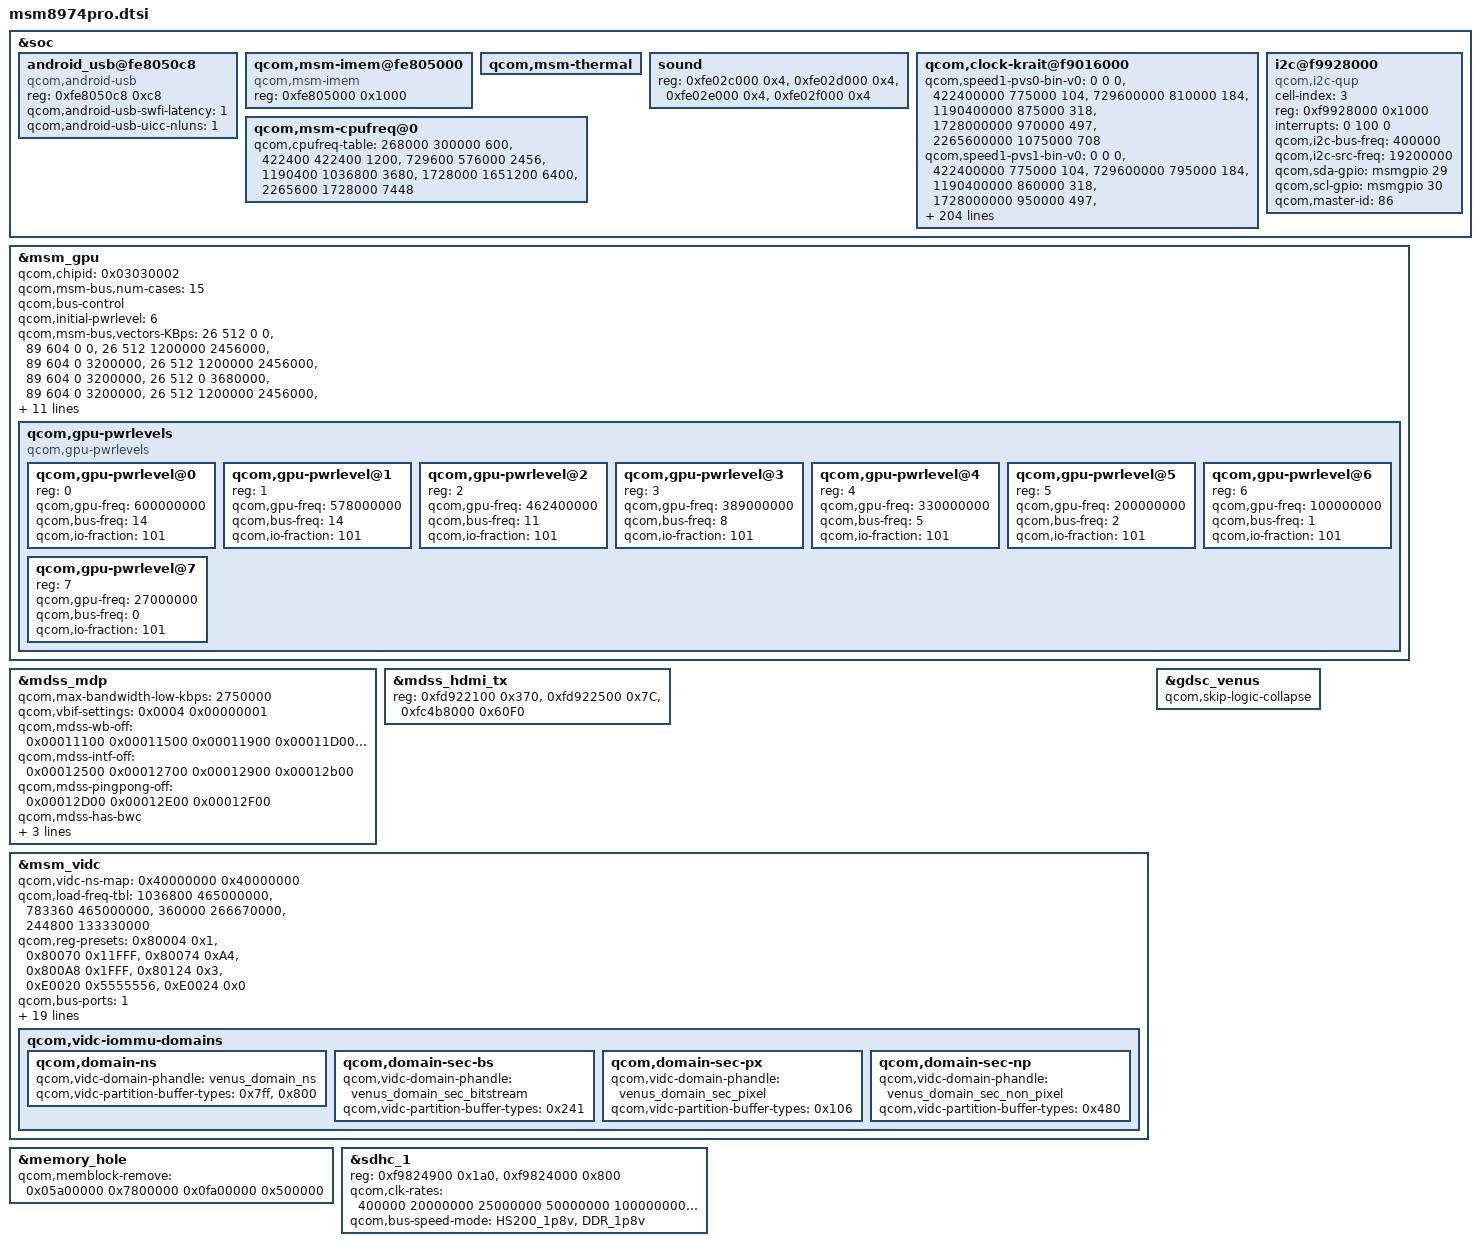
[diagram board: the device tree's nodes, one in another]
/* Copyright (c) 2013-2014, The Linux Foundation. All rights reserved.
 *
 * This program is free software; you can redistribute it and/or modify
 * it under the terms of the GNU General Public License version 2 and
 * only version 2 as published by the Free Software Foundation.
 *
 * This program is distributed in the hope that it will be useful,
 * but WITHOUT ANY WARRANTY; without even the implied warranty of
 * MERCHANTABILITY or FITNESS FOR A PARTICULAR PURPOSE.  See the
 * GNU General Public License for more details.
 */

/*
 * As a general rule, only version-specific property overrides should be placed
 * inside this file. However, device definitions should be placed inside the
 * msm8974.dtsi file.
 */

/include/ "msm8974.dtsi"
/include/ "msm8974-v2-iommu.dtsi"
/include/ "msm8974-v2-iommu-domains.dtsi"
/include/ "msm8974pro-pm.dtsi"
/include/ "msm8974pro-ion.dtsi"

&soc {
	android_usb@fe8050c8 {
		compatible = "qcom,android-usb";
		reg = <0xfe8050c8 0xc8>;
		qcom,android-usb-swfi-latency = <1>;
		qcom,android-usb-uicc-nluns = /bits/ 8 <1>;
	};

	qcom,msm-imem@fe805000 {
		compatible = "qcom,msm-imem";
		reg = <0xfe805000 0x1000>; /* Address and size of IMEM */
	};

	qcom,msm-thermal {
		/delete-property/ qcom,pmic-sw-mode-temp;
		/delete-property/ qcom,pmic-sw-mode-temp-hysteresis;
		/delete-property/ qcom,pmic-sw-mode-regs;
	};

	sound {
		reg = <0xfe02c000 0x4>,
		      <0xfe02d000 0x4>,
		      <0xfe02e000 0x4>,
		      <0xfe02f000 0x4>;
		reg-names = "lpaif_pri_mode_muxsel",
			    "lpaif_sec_mode_muxsel",
			    "lpaif_tert_mode_muxsel",
			    "lpaif_quat_mode_muxsel";
	};

	qcom,clock-krait@f9016000 {
		qcom,speed1-pvs0-bin-v0 =
			<          0       0    0 >,
			<  422400000  775000  104 >,
			<  729600000  810000  184 >,
			< 1190400000  875000  318 >,
			< 1728000000  970000  497 >,
			< 2265600000 1075000  708 >;

		qcom,speed1-pvs1-bin-v0 =
			<          0       0    0 >,
			<  422400000  775000  104 >,
			<  729600000  795000  184 >,
			< 1190400000  860000  318 >,
			< 1728000000  950000  497 >,
			< 2265600000 1050000  708 >;

		qcom,speed1-pvs2-bin-v0 =
			<          0       0    0 >,
			<  422400000  750000  104 >,
			<  729600000  780000  184 >,
			< 1190400000  840000  318 >,
			< 1728000000  930000  497 >,
			< 2265600000 1025000  708 >;

		qcom,speed1-pvs3-bin-v0 =
			<          0       0    0 >,
			<  422400000  750000  104 >,
			<  729600000  765000  184 >,
			< 1190400000  825000  318 >,
			< 1728000000  910000  497 >,
			< 2265600000 1000000  708 >;

		qcom,speed1-pvs4-bin-v0 =
			<          0       0    0 >,
			<  422400000  750000  104 >,
			<  729600000  755000  184 >,
			< 1190400000  815000  318 >,
			< 1728000000  895000  497 >,
			< 2265600000  975000  708 >;

		qcom,speed1-pvs5-bin-v0 =
			<          0       0    0 >,
			<  422400000  725000  104 >,
			<  729600000  745000  184 >,
			< 1190400000  805000  318 >,
			< 1728000000  875000  497 >,
			< 2265600000  950000  708 >;

		qcom,speed1-pvs6-bin-v0 =
			<          0       0    0 >,
			<  422400000  725000  104 >,
			<  729600000  735000  184 >,
			< 1190400000  795000  318 >,
			< 1728000000  860000  497 >,
			< 2265600000  925000  708 >;

		qcom,speed3-pvs0-bin-v0 =
			<          0       0    0 >,
			<  422400000  800000  106 >,
			<  729600000  820000  186 >,
			< 1190400000  880000  319 >,
			< 1728000000  960000  493 >,
			< 2265600000 1065000  700 >;

		qcom,speed3-pvs1-bin-v0 =
			<          0       0    0 >,
			<  422400000  800000  106 >,
			<  729600000  800000  186 >,
			< 1190400000  855000  319 >,
			< 1728000000  935000  493 >,
			< 2265600000 1040000  700 >;

		qcom,speed3-pvs2-bin-v0 =
			<          0       0    0 >,
			<  422400000  775000  106 >,
			<  729600000  775000  186 >,
			< 1190400000  830000  319 >,
			< 1728000000  910000  493 >,
			< 2265600000 1015000  700 >;

		qcom,speed3-pvs3-bin-v0 =
			<          0       0    0 >,
			<  422400000  775000  106 >,
			<  729600000  775000  186 >,
			< 1190400000  805000  319 >,
			< 1728000000  885000  493 >,
			< 2265600000  990000  700 >;

		qcom,speed3-pvs4-bin-v0 =
			<          0       0    0 >,
			<  422400000  775000  106 >,
			<  729600000  775000  186 >,
			< 1190400000  780000  319 >,
			< 1728000000  860000  493 >,
			< 2265600000  965000  700 >;

		qcom,speed3-pvs5-bin-v0 =
			<          0       0    0 >,
			<  422400000  750000  106 >,
			<  729600000  750000  186 >,
			< 1190400000  760000  319 >,
			< 1728000000  835000  493 >,
			< 2265600000  940000  700 >;

		qcom,speed3-pvs6-bin-v0 =
			<          0       0    0 >,
			<  422400000  750000  106 >,
			<  729600000  750000  186 >,
			< 1190400000  750000  319 >,
			< 1728000000  815000  493 >,
			< 2265600000  940000  700 >;

		qcom,speed1-pvs0-bin-v1 =
			<          0       0    0 >,
			<  268000000  800000   76 >,
			<  422400000  820000  108 >,
			<  729600000  860000  193 >,
			< 1190400000  920000  330 >,
			< 1728000000 1015000  515 >,
			< 2265600000 1120000  738 >;

		qcom,speed1-pvs1-bin-v1 =
			<          0       0    0 >,
			<  268000000  800000   76 >,
			<  422400000  810000  108 >,
			<  729600000  850000  193 >,
			< 1190400000  910000  330 >,
			< 1728000000 1005000  515 >,
			< 2265600000 1110000  738 >;

		qcom,speed1-pvs2-bin-v1 =
			<          0       0    0 >,
			<  268000000  800000   76 >,
			<  422400000  800000  108 >,
			<  729600000  840000  193 >,
			< 1190400000  900000  330 >,
			< 1728000000  995000  515 >,
			< 2265600000 1100000  738 >;

		qcom,speed1-pvs3-bin-v1 =
			<          0       0    0 >,
			<  268000000  800000   76 >,
			<  422400000  800000  108 >,
			<  729600000  830000  193 >,
			< 1190400000  890000  330 >,
			< 1728000000  985000  515 >,
			< 2265600000 1090000  738 >;

		qcom,speed1-pvs4-bin-v1 =
			<          0       0    0 >,
			<  268000000  800000   76 >,
			<  422400000  800000  108 >,
			<  729600000  820000  193 >,
			< 1190400000  880000  330 >,
			< 1728000000  975000  515 >,
			< 2265600000 1080000  738 >;

		qcom,speed1-pvs5-bin-v1 =
			<          0       0    0 >,
			<  268000000  800000   76 >,
			<  422400000  800000  108 >,
			<  729600000  810000  193 >,
			< 1190400000  870000  330 >,
			< 1728000000  965000  515 >,
			< 2265600000 1070000  738 >;

		qcom,speed1-pvs6-bin-v1 =
			<          0       0    0 >,
			<  268000000  775000   76 >,
			<  422400000  775000  108 >,
			<  729600000  805000  193 >,
			< 1190400000  865000  330 >,
			< 1728000000  955000  515 >,
			< 2265600000 1060000  738 >;

		qcom,speed1-pvs7-bin-v1 =
			<          0       0    0 >,
			<  268000000  775000   76 >,
			<  422400000  775000  108 >,
			<  729600000  800000  193 >,
			< 1190400000  860000  330 >,
			< 1728000000  945000  515 >,
			< 2265600000 1050000  738 >;

		qcom,speed1-pvs8-bin-v1 =
			<          0       0    0 >,
			<  268000000  775000   76 >,
			<  422400000  775000  108 >,
			<  729600000  790000  193 >,
			< 1190400000  850000  330 >,
			< 1728000000  935000  515 >,
			< 2265600000 1040000  738 >;

		qcom,speed1-pvs9-bin-v1 =
			<          0       0    0 >,
			<  268000000  775000   76 >,
			<  422400000  775000  108 >,
			<  729600000  785000  193 >,
			< 1190400000  845000  330 >,
			< 1728000000  925000  515 >,
			< 2265600000 1030000  738 >;

		qcom,speed1-pvs10-bin-v1 =
			<          0       0    0 >,
			<  268000000  775000   76 >,
			<  422400000  775000  108 >,
			<  729600000  780000  193 >,
			< 1190400000  840000  330 >,
			< 1728000000  915000  515 >,
			< 2265600000 1020000  738 >;

		qcom,speed1-pvs11-bin-v1 =
			<          0       0    0 >,
			<  268000000  775000   76 >,
			<  422400000  775000  108 >,
			<  729600000  775000  193 >,
			< 1190400000  835000  330 >,
			< 1728000000  905000  515 >,
			< 2265600000 1010000  738 >;

		qcom,speed1-pvs12-bin-v1 =
			<          0       0    0 >,
			<  268000000  775000   76 >,
			<  422400000  775000  108 >,
			<  729600000  775000  193 >,
			< 1190400000  830000  330 >,
			< 1728000000  900000  515 >,
			< 2265600000 1000000  738 >;

		qcom,speed1-pvs13-bin-v1 =
			<          0       0    0 >,
			<  268000000  775000   76 >,
			<  422400000  775000  108 >,
			<  729600000  775000  193 >,
			< 1190400000  825000  330 >,
			< 1728000000  895000  515 >,
			< 2265600000  990000  738 >;

		qcom,speed1-pvs14-bin-v1 =
			<          0       0    0 >,
			<  268000000  750000   76 >,
			<  422400000  750000  108 >,
			<  729600000  760000  193 >,
			< 1190400000  820000  330 >,
			< 1728000000  890000  515 >,
			< 2265600000  980000  738 >;

		qcom,speed1-pvs15-bin-v1 =
			<          0       0    0 >,
			<  268000000  750000   76 >,
			<  422400000  750000  108 >,
			<  729600000  755000  193 >,
			< 1190400000  815000  330 >,
			< 1728000000  885000  515 >,
			< 2265600000  970000  738 >;

		qcom,speed3-pvs0-bin-v1 =
			<          0       0    0 >,
			<  422400000  800000  106 >,
			<  729600000  840000  189 >,
			< 1190400000  900000  324 >,
			< 1728000000  980000  501 >,
			< 2265600000 1085000  716 >;

		qcom,speed3-pvs1-bin-v1 =
			<          0       0    0 >,
			<  422400000  800000  106 >,
			<  729600000  830000  189 >,
			< 1190400000  890000  324 >,
			< 1728000000  970000  501 >,
			< 2265600000 1075000  716 >;

		qcom,speed3-pvs2-bin-v1 =
			<          0       0    0 >,
			<  422400000  800000  106 >,
			<  729600000  820000  189 >,
			< 1190400000  880000  324 >,
			< 1728000000  960000  501 >,
			< 2265600000 1065000  716 >;

		qcom,speed3-pvs3-bin-v1 =
			<          0       0    0 >,
			<  422400000  800000  106 >,
			<  729600000  810000  189 >,
			< 1190400000  870000  324 >,
			< 1728000000  950000  501 >,
			< 2265600000 1055000  716 >;

		qcom,speed3-pvs4-bin-v1 =
			<          0       0    0 >,
			<  422400000  800000  106 >,
			<  729600000  800000  189 >,
			< 1190400000  860000  324 >,
			< 1728000000  940000  501 >,
			< 2265600000 1045000  716 >;

		qcom,speed3-pvs5-bin-v1 =
			<          0       0    0 >,
			<  422400000  800000  106 >,
			<  729600000  800000  189 >,
			< 1190400000  850000  324 >,
			< 1728000000  930000  501 >,
			< 2265600000 1035000  716 >;

		qcom,speed3-pvs6-bin-v1 =
			<          0       0    0 >,
			<  422400000  775000  106 >,
			<  729600000  780000  189 >,
			< 1190400000  840000  324 >,
			< 1728000000  920000  501 >,
			< 2265600000 1025000  716 >;

		qcom,speed3-pvs7-bin-v1 =
			<          0       0    0 >,
			<  422400000  775000  106 >,
			<  729600000  780000  189 >,
			< 1190400000  835000  324 >,
			< 1728000000  910000  501 >,
			< 2265600000 1015000  716 >;

		qcom,speed3-pvs8-bin-v1 =
			<          0       0    0 >,
			<  422400000  775000  106 >,
			<  729600000  775000  189 >,
			< 1190400000  825000  324 >,
			< 1728000000  900000  501 >,
			< 2265600000 1005000  716 >;

		qcom,speed3-pvs9-bin-v1 =
			<          0       0    0 >,
			<  422400000  775000  106 >,
			<  729600000  775000  189 >,
			< 1190400000  820000  324 >,
			< 1728000000  890000  501 >,
			< 2265600000  995000  716 >;

		qcom,speed3-pvs10-bin-v1 =
			<          0       0    0 >,
			<  422400000  775000  106 >,
			<  729600000  775000  189 >,
			< 1190400000  815000  324 >,
			< 1728000000  885000  501 >,
			< 2265600000  985000  716 >;

		qcom,speed3-pvs11-bin-v1 =
			<          0       0    0 >,
			<  422400000  775000  106 >,
			<  729600000  775000  189 >,
			< 1190400000  810000  324 >,
			< 1728000000  880000  501 >,
			< 2265600000  975000  716 >;

		qcom,speed3-pvs12-bin-v1 =
			<          0       0    0 >,
			<  422400000  775000  106 >,
			<  729600000  775000  189 >,
			< 1190400000  805000  324 >,
			< 1728000000  875000  501 >,
			< 2265600000  965000  716 >;

		qcom,speed3-pvs13-bin-v1 =
			<          0       0    0 >,
			<  422400000  775000  106 >,
			<  729600000  775000  189 >,
			< 1190400000  800000  324 >,
			< 1728000000  870000  501 >,
			< 2265600000  955000  716 >;

		qcom,speed3-pvs14-bin-v1 =
			<          0       0    0 >,
			<  422400000  750000  106 >,
			<  729600000  750000  189 >,
			< 1190400000  795000  324 >,
			< 1728000000  865000  501 >,
			< 2265600000  945000  716 >;

		qcom,speed3-pvs15-bin-v1 =
			<          0       0    0 >,
			<  422400000  750000  106 >,
			<  729600000  750000  189 >,
			< 1190400000  790000  324 >,
			< 1728000000  860000  501 >,
			< 2265600000  935000  716 >;
	};

	qcom,msm-cpufreq@0 {
		qcom,cpufreq-table =
			<  268000  300000  600 /*  75 MHz */ >,
			<  422400  422400 1200 /* 150 MHz */ >,
			<  729600  576000 2456 /* 307 MHz */ >,
			< 1190400 1036800 3680 /* 460 MHz */ >,
			< 1728000 1651200 6400 /* 800 MHz */ >,
			< 2265600 1728000 7448 /* 931 MHz */ >;

	};

	i2c@f9928000 { /* BLSP-1 QUP-6 */
		cell-index = <3>;
		compatible = "qcom,i2c-qup";
		reg = <0xf9928000 0x1000>;
		#address-cells = <1>;
		#size-cells = <0>;
		reg-names = "qup_phys_addr";
		interrupts = <0 100 0>;
		interrupt-names = "qup_err_intr";
		qcom,i2c-bus-freq = <400000>;
		qcom,i2c-src-freq = <19200000>;
		qcom,sda-gpio = <&msmgpio 29 0>;
		qcom,scl-gpio = <&msmgpio 30 0>;
		qcom,master-id = <86>;
	};
};

/* GPU overrides */
&msm_gpu {
	/* Updated chip ID */
	qcom,chipid = <0x03030002>;
	qcom,msm-bus,num-cases = <15>;
	qcom,bus-control;
	qcom,initial-pwrlevel = <6>;

	/* Updated bus bandwidth requirements */
	qcom,msm-bus,vectors-KBps =
		/* Off */
		<26 512 0 0>, <89 604 0 0>,
		/* Sub-SVS / SVS */
		<26 512 1200000 2456000>, <89 604 0 3200000>,
		/* SVS */
		<26 512 1200000 2456000>, <89 604 0 3200000>,
		/* low Nominal / SVS */
		<26 512 0 3680000>, <89 604 0 3200000>,
		/* SVS / low Nominal */
		<26 512 1200000 2456000>, <89 604 0 5280000>,
		/* low Nominal / low Nominal */
		<26 512 0 3680000>, <89 604 0 5280000>,
		/* Nominal / low Nominal */
		<26 512 0 4912000>, <89 604 0 5280000>,
		/* low Nominal / Nominal */
		<26 512 0 3680000>, <89 604 0 6224000>,
		/* Nominal / Nominal */
		<26 512 0 4912000>, <89 604 0 6224000>,
		/* low Turbo / Nominal */
		<26 512 0 6400000>, <89 604 0 6224000>,
		/* Nominal / low Turbo */
		<26 512 0 4912000>, <89 604 0 7398000>,
		/* low Turbo / low Turbo */
		<26 512 0 6400000>, <89 604 0 7398000>,
		/* Turbo / low Turbo */
		<26 512 0 7464000>, <89 604 0 7398000>,
		/* Nominal / Turbo */
		<26 512 0 4912000>, <89 604 0 9248000>,
		/* Turbo / Turbo */
		<26 512 0 7464000>, <89 604 0 9248000>;

       qcom,gpu-pwrlevels {
               #address-cells = <1>;
               #size-cells = <0>;

               compatible = "qcom,gpu-pwrlevels";

		qcom,gpu-pwrlevel@0 {
                       reg = <0>;
                       qcom,gpu-freq = <600000000>;
                       qcom,bus-freq = <14>;
                       qcom,io-fraction = <101>;
               };

               qcom,gpu-pwrlevel@1 {
                       reg = <1>;
                       qcom,gpu-freq = <578000000>;
                       qcom,bus-freq = <14>;
                       qcom,io-fraction = <101>;
               };

               qcom,gpu-pwrlevel@2 {
                       reg = <2>;
                       qcom,gpu-freq = <462400000>;
                       qcom,bus-freq = <11>;
                       qcom,io-fraction = <101>;
               };

               qcom,gpu-pwrlevel@3 {
                       reg = <3>;
                       qcom,gpu-freq = <389000000>;
                       qcom,bus-freq = <8>;
                       qcom,io-fraction = <101>;
               };

               qcom,gpu-pwrlevel@4 {
                       reg = <4>;
                       qcom,gpu-freq = <330000000>;
                       qcom,bus-freq = <5>;
                       qcom,io-fraction = <101>;
               };

               qcom,gpu-pwrlevel@5 {
                       reg = <5>;
                       qcom,gpu-freq = <200000000>;
                       qcom,bus-freq = <2>;
                       qcom,io-fraction = <101>;
               };

               qcom,gpu-pwrlevel@6 {
                       reg = <6>;
                       qcom,gpu-freq = <100000000>;
                       qcom,bus-freq = <1>;
                       qcom,io-fraction = <101>;
                };

               qcom,gpu-pwrlevel@7 {
                       reg = <7>;
                       qcom,gpu-freq = <27000000>;
                       qcom,bus-freq = <0>;
                       qcom,io-fraction = <101>;
                };
       };
};

&mdss_mdp {
	qcom,max-bandwidth-low-kbps = <2750000>;
	qcom,vbif-settings = <0x0004 0x00000001>;

	qcom,mdss-wb-off = <0x00011100 0x00011500
			    0x00011900 0x00011D00 0x00012100>;
	qcom,mdss-intf-off = <0x00012500 0x00012700
			      0x00012900 0x00012b00>;
	qcom,mdss-pingpong-off = <0x00012D00 0x00012E00 0x00012F00>;
	qcom,mdss-has-bwc;
	qcom,mdss-has-decimation;
	qcom,mdss-ad-off = <0x0013100 0x00013300>;
	vdd-cx-supply = <&pm8841_s2_corner>;
};

&mdss_hdmi_tx {
	reg =	<0xfd922100 0x370>,
		<0xfd922500 0x7C>,
		<0xfc4b8000 0x60F0>;
	reg-names = "core_physical", "phy_physical", "qfprom_physical";
};

&msm_vidc {
	qcom,vidc-ns-map = <0x40000000 0x40000000>;
	qcom,load-freq-tbl = <1036800 465000000>,
		<783360 465000000>,
		<360000 266670000>,
		<244800 133330000>;
	qcom,reg-presets = <0x80004 0x1>,
		<0x80070 0x11FFF>,
		<0x80074 0xA4>,
		<0x800A8 0x1FFF>,
		<0x80124 0x3>,
		<0xE0020 0x5555556>,
		<0xE0024 0x0>;
	qcom,bus-ports = <1>;
	qcom,enc-ocmem-ab-ib = <0 0>,
		<138000 1034000>,
		<414000 1034000>,
		<940000 1034000>,
		<1880000 2068000>,
		<3008000 3309000>,
		<3760000 4136000>,
		<4468000 2457000>;
	qcom,dec-ocmem-ab-ib = <0 0>,
		<176000 519000>,
		<456000 519000>,
		<864000 629000>,
		<1728000 1038000>,
		<2766000 1661000>,
		<3456000 2076000>,
		<3662000 2198000>;
	qcom,enc-ddr-ab-ib = <0 0>,
		<120000 302000>,
		<364000 302000>,
		<804000 302000>,
		<1608000 604000>,
		<2576000 967000>,
		<4680000 1404000>,
		<4988000 1496000>;
	qcom,dec-ddr-ab-ib = <0 0>,
		<208000 303000>,
		<536000 1600000>,
		<1012000 1600000>,
		<2024000 1600000>,
		<3240000 1600000>,
		<4048000 1600000>,
		<4264000 1600000>;
    /*
     * Performance is guaranteed only upto POR specification. Anything
     * above that specification is best effort and might even be rejected.
     */
	qcom,max-hw-load = <1281600>; /* max(4k X 2304 @ 24, 4k X 2160 @ 30) + 1080p @ 30 */
	qcom,buffer-type-tz-usage-table = <0x241 0x1>,
					<0x106 0x2>,
					<0x480 0x3>;
	qcom,vidc-iommu-domains {
		qcom,domain-ns {
			qcom,vidc-domain-phandle = <&venus_domain_ns>;
			qcom,vidc-partition-buffer-types = <0x7ff>,
							<0x800>;
		};
		qcom,domain-sec-bs {
			qcom,vidc-domain-phandle = <&venus_domain_sec_bitstream>;
			qcom,vidc-partition-buffer-types = <0x241>;
		};
		qcom,domain-sec-px {
			qcom,vidc-domain-phandle = <&venus_domain_sec_pixel>;
			qcom,vidc-partition-buffer-types = <0x106>;
		};
		qcom,domain-sec-np {
			qcom,vidc-domain-phandle = <&venus_domain_sec_non_pixel>;
			qcom,vidc-partition-buffer-types = <0x480>;
		};
	};
};

&memory_hole {
	qcom,memblock-remove = <0x05a00000 0x7800000
				0x0fa00000 0x500000>; /* Address and size of the hole */
};

&gdsc_venus {
	qcom,skip-logic-collapse;
};

&sdhc_1 {
	reg = <0xf9824900 0x1a0>, <0xf9824000 0x800>;

	qcom,clk-rates = <400000 20000000 25000000 50000000 100000000 200000000>;
	qcom,bus-speed-mode = "HS200_1p8v", "DDR_1p8v";
};
